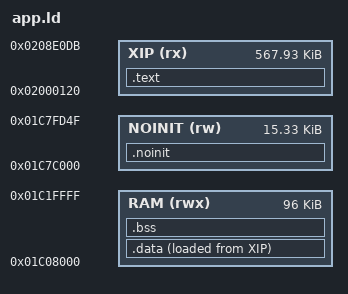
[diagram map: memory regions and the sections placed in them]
/* SPDX-License-Identifier: MPL-2.0
 * Copyright (C) 2026 Leo Kuroshita (@kurogedelic), Hügelton Instruments */
/* Memory map of a standalone FM-1 app: code and constants run in place from XIP
 * (app.bin offset 0 = 0x02000120); .data is copied to RAM by fm1_cstart.
 * Stacks sit above the RAM with 256-byte guard bands; NOINIT survives resets.
 * 0x01C7FD50.. is reserved (boot info, mailbox, vector table). */
MEMORY
{
    XIP    (rx)  : ORIGIN = 0x02000120, LENGTH = 0x8DFBC
    RAM    (rwx) : ORIGIN = 0x01C08000, LENGTH = 96K
    NOINIT (rw)  : ORIGIN = 0x01C7C000, LENGTH = 0x3D50
}
SECTIONS
{
    .text : { KEEP(*(.text.crt0)) *(.text*) *(.rodata*) . = ALIGN(4); _etext = .; } > XIP
    .data : { . = ALIGN(4); _data_start = .; *(.data*) *(.sdata*) . = ALIGN(4); _data_end = .; } > RAM AT > XIP
    _data_load = LOADADDR(.data);
    .bss (NOLOAD) : { _bss_start = .; *(.bss*) *(.sbss*) *(COMMON) . = ALIGN(4); _bss_end = .; } > RAM
    .noinit (NOLOAD) : { *(.noinit*) } > NOINIT
    _rt_start = 0; _rt_end = 0;
    _guard0 = 0x01C74000; _ustack_lo = 0x01C74100; _ustack_top = 0x01C7A000;
    _guard1 = 0x01C7A000; _sstack_lo = 0x01C7A100; _sstack_top = 0x01C7C000;
    /DISCARD/ : { *(.comment) *(.note*) }
}
